# SIM3C166_B register map
File version: 1
CPU: 
Registers are 32-bit, read-write, reset 0x0 unless marked. A register's access mark holds for its fields unless they carry their own. Offsets are from the block's base; [hi:lo] are bit positions; {n}, {i} and the like mark numbered series; 'fields as' and 'values as' point back to an identical list.

## USART_0
Base 0x40000000
Same registers: USART_1 0x40001000
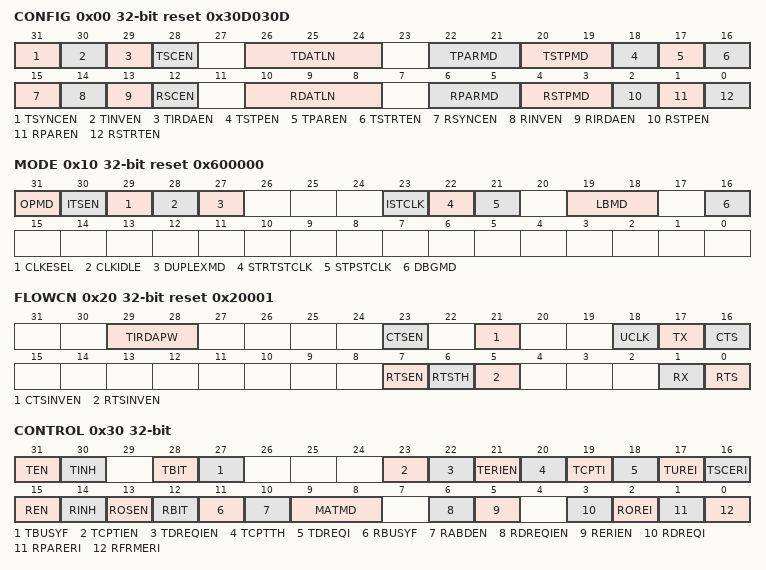
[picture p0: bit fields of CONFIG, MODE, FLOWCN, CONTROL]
0x00 CONFIG reset 0x30D030D — Module Configuration
  [31] TSYNCEN — Transmitter Synchronous Mode Enable.
    0=DISABLED (The transmitter operates in asynchronous mode.); 1=ENABLED (The transmitter operates in synchronous mode.)
  [30] TINVEN — Transmitter Invert Enable.
    0=DISABLED (Do not invert the TX pin signals (the TX idle state is high).); 1=ENABLED (Invert the TX pin signals (the TX idle state is low).)
  [29] TIRDAEN — Transmitter IrDA Enable.
    0=DISABLED (Disable IrDA transmit mode.); 1=ENABLED (Enable IrDA transmit mode.)
  [28] TSCEN — Transmitter Smartcard Parity Response Enable.
    0=DISABLED (The transmitter does not check for a Smartcard parity error response.); 1=ENABLED (The transmitter checks for a Smartcard parity error response.)
  [26:24] TDATLN — Transmitter Data Length.
    {v}={v+5}_BITS (v=0..3); 4=9_BITS_FIFO (9 bits. The 9th bit is taken from the FIFO data (normal mode).); 5=9_BITS_TBIT (9 bits. The 9th bit is set by the value of TBIT (fixed mode).)
  [22:21] TPARMD — Transmitter Parity Mode.
    0=ODD (Odd Parity.); 1=EVEN (Even Parity.); 2=MARK (Set (Parity = 1).); 3=SPACE (Clear (Parity = 0).)
  [20:19] TSTPMD — Transmitter Stop Mode.
    0=0P5_STOP (0.5 stop bit.); 1=1_STOP (1 stop bit.); 2=1P5_STOP (1.5 stop bits.); 3=2_STOP (2 stop bits.)
  [18] TSTPEN — Transmitter Stop Enable.
    0=DISABLED (Do not send stop bits during transmissions.); 1=ENABLED (Send stop bits during transmissions.)
  [17] TPAREN — Transmitter Parity Enable.
    0=DISABLED (Do not send a parity bit during transmissions.); 1=ENABLED (Send a parity bit during transmissions.)
  [16] TSTRTEN — Transmitter Start Enable.
    0=DISABLED (Do not generate a start bit during transmissions.); 1=ENABLED (Generate a start bit during transmissions.)
  [15] RSYNCEN — Receiver Synchronous Mode Enable.
    0=DISABLED (The receiver operates in asynchronous mode.); 1=ENABLED (The receiver operates in synchronous mode.)
  [14] RINVEN — Receiver Invert Enable.
    0=DISABLED (Do not invert the RX pin signals (the RX idle state is high).); 1=ENABLED (Invert the RX pin signals (the RX idle state is low).)
  [13] RIRDAEN — Receiver IrDA Enable.
    0=DISABLED (The receiver does not operate in IrDA mode.); 1=ENABLED (The receiver operates in IrDA mode.)
  [12] RSCEN — Receiver Smartcard Parity Response Enable.
    0=DISABLED (The receiver does not send a Smartcard parity error response.); 1=ENABLED (The receiver sends a Smartcard parity response.)
  [10:8] RDATLN — Receiver Data Length.
    {v}={v+5}_BITS (v=0..3); 4=9_BITS_STORED (9 bits. The 9th bit is stored in the FIFO (normal mode).); 5=9_BITS_MATCH (9 bits. The 9th bit is not stored in the FIFO (fixed mode). This mode is used when the 9th bit is only used for match operations (see MATMD).)
  [6:5] RPARMD — Receiver Parity Mode.
    values as TPARMD
  [4:3] RSTPMD — Receiver Stop Mode.
    values as TSTPMD
  [2] RSTPEN — Receiver Stop Enable.
    0=DISABLED (Do not expect stop bits during receptions.); 1=ENABLED (Expect stop bits during receptions.)
  [1] RPAREN — Receiver Parity Enable.
    0=DISABLED (Do not expect a parity bit during receptions.); 1=ENABLED (Expect a parity bit during receptions.)
  [0] RSTRTEN — Receiver Start Enable.
    0=DISABLED (Do not expect a start bit during receptions.); 1=ENABLED (Expect a start bit during receptions.)
0x10 MODE reset 0x600000 — Module Mode Select
  [31] OPMD — Operational Mode.
    0=SLAVE (The USART operates as a slave.); 1=MASTER (The USART operates as a master.)
  [30] ITSEN — Idle TX/UCLK Tristate Enable.
    0=DISABLED (The TX and UCLK (if in synchronous master mode) pins are always an output in this mode, even when idle.); 1=ENABLED (The TX pin is tristated when idle. If ISTCLK is cleared to 0 and the transmitter is configured in synchronous master mode, the UCLK pin will also be tristated when idle.)
  [29] CLKESEL — Clock Edge Select.
    0=FALLING (The clock falls in the middle of each bit.); 1=RISING (The clock rises in the middle of each bit.)
  [28] CLKIDLE — Clock Idle State.
    0=IDLE_LOW (The synchronous clock is low when idle.); 1=IDLE_HIGH (The synchronous clock is high when idle.)
  [27] DUPLEXMD — Duplex Mode.
    0=FULL_DUPLEX (Full-duplex mode. The transmitter and receiver can operate simultaneously.); 1=HALF_DUPLEX (Half-duplex mode. The transmitter automatically inhibits when the receiver is active and the receiver automatically inhibits when the transmitter is active.)
  [23] ISTCLK — Idle Clock Control.
    0=DISABLED (When the USART is a clock master and CLKESEL is not equal to CLKIDLE, the clock is held idle between transmissions. When the USART is a clock master and CLKESEL equals CLKIDEL, the clock will still be generated between transmissions. When the USART is a clock slave, the USART will begin transmissions without waiting for the next clock edge.); 1=ENABLED (When the USART is a clock master, the clock is generated between transmissions or receptions. When the USART is a clock slave, the USART will wait until the next clock edge before transmitting.)
  [22] STRTSTCLK — Start State Clock Control.
    0=DISABLED (When the USART is a clock master, the clock is held idle during a start bit.); 1=ENABLED (When the USART is a clock master, the clock is generated during a start bit.)
  [21] STPSTCLK — Stop State Clock Control.
    0=DISABLED (When the USART is a clock master, the clock is not generated during stop bits.); 1=ENABLED (When the USART is a clock master, the clock is generated during stop bits.)
  [19:18] LBMD — Loop Back Mode.
    0=DISABLED (Loop back is disabled and the TX and RX signals are connected to the corresponding external pins.); 1=RXONLY (Receive loop back. The receiver input path is disconnected from the RX pin and internally connected to the transmitter. Data transmitted will be sent out on TX and also received by the device.); 2=TXONLY (Transmit loop back. The transmitter output path is disconnected from the TX pin and the RX input pin is internally looped back out to the TX pin. Data received at RX will be received by the device and also sent directly back out on TX.); 3=BOTH (Full loop back. Internally, the transmitter output is routed back to the receiver input. Neither the transmitter nor receiver are connected to external device pins. The device pin RX is looped back to TX in a similar fashion. Data transmitted on TX will be sent directly back in on RX.)
  [16] DBGMD — USART Debug Mode.
    0=RUN (The USART module will continue to operate while the core is halted in debug mode.); 1=HALT (A debug breakpoint will cause the USART module to halt. Any active transmissions and receptions will complete first.)
0x20 FLOWCN reset 0x20001 — Flow Control
  [29:28] TIRDAPW — Transmit IrDA Pulse Width.
    0=1_16TH (The IrDA pulse width is 1/16th of a bit period.); 1=1_8TH (The IrDA pulse width is 1/8th of a bit period.); 2=3_16TH (The IrDA pulse width is 3/16th of a bit period.); 3=1_4TH (The IrDA pulse width is 1/4th of a bit period.)
  [23] CTSEN — CTS Enable.
    0=DISABLED (The CTS pin state does not affect transmissions.); 1=ENABLED (Transmissions will begin only if the CTS pin (after optional inversion) is low.)
  [21] CTSINVEN — CTS Invert Enable.
    0=DISABLED (The USART does not invert CTS.); 1=ENABLED (The USART inverts CTS.)
  [18] UCLK — UCLK State.
    0=LOW (The UCLK pin is low.); 1=HIGH (The UCLK pin is high.)
  [17] TX — TX State.
    0=LOW (The TX pin (before optional inversion) is low.); 1=HIGH (The TX pin (before optional inversion) is high.)
  [16] CTS ro — CTS State.
    0=LOW (Indicates the CTS pin state (after optional inversion) is low.); 1=HIGH (Indicates the CTS pin state (after optional inversion) is high.)
  [7] RTSEN — RTS Enable.
    0=DISABLED (The RTS state is not changed by hardware. The RTS bit can be written only when hardware RTS is disabled (RTSEN = 0).); 1=ENABLED (Hardware sets RTS when the receive FIFO is at or above the threshold set by RTSTH and clears RTS otherwise.)
  [6] RTSTH — RTS Threshold Control.
    0=FULL (RTS is de-asserted when the receive FIFO and shift register are full and no more incoming data can be stored.); 1=ONE_BYTE_FREE (RTS is de-asserted when the receive FIFO and shift register are nearly full and only one more data can be received.)
  [5] RTSINVEN — RTS Invert Enable.
    0=DISABLED (The USART does not invert the RTS signal before driving the pin.); 1=ENABLED (The USART inverts the RTS signal driving the pin.)
  [1] RX ro — RX Pin Status.
    0=LOW (RX pin (after optional inversion) is low.); 1=HIGH (RX pin (after optional inversion) is high.)
  [0] RTS — RTS State.
    0=LOW (RTS pin (before optional inversion) is driven low.); 1=HIGH (RTS pin (before optional inversion) is driven high.)
0x30 CONTROL — Module Control
  [31] TEN — Transmitter Enable.
    0=DISABLED (Disable the transmitter. When cleared, the transmitter immediately aborts any active transmission. Clearing this bit does not automatically flush the transmit FIFO.); 1=ENABLED (Enable the transmitter. The transmitter will initiate a transmission when data becomes available in the transmit FIFO.)
  [30] TINH — Transmit Inhibit.
    0=INACTIVE (The transmitter operates normally.); 1=ACTIVE (Transmissions are inhibited. The transmitter will stall after any current transmission is complete.)
  [28] TBIT — Last Transmit Bit.
    0=NOT_SET; 1=SET
  [27] TBUSYF ro — Transmitter Busy Flag.
    0=NOT_SET (The USART transmitter is idle.); 1=SET (The USART transmitter is active and transmitting.)
  [23] TCPTIEN — Transmit Complete Interrupt Enable.
    0=DISABLED (Disable the transmit complete interrupt.); 1=ENABLED (Enable the transmit complete interrupt. A transmit interrupt is generated when TCPTI is set to 1.)
  [22] TDREQIEN — Transmit Data Request Interrupt Enable.
    0=DISABLED (Disable the transmit data request interrupt.); 1=ENABLED (Enable the transmit data request interrupt. A transmit interrupt is asserted when TDREQI is set to 1.)
  [21] TERIEN — Transmit Error Interrupt Enable.
    0=DISABLED (Disable the transmit error interrupt.); 1=ENABLED (Enable the transmit error interrupt. A transmit interrupt is generated when TUREI or TSCERI is set to 1.)
  [20] TCPTTH — Transmit Complete Threshold.
    0=SET_ON_TX (A transmit is completed (TCPTI = 1) at the end of each transmission.); 1=SET_ON_EMPTY (A transmit is completed (TCPTI = 1) only at the end of a transmission when no more data is available to transmit.)
  [19] TCPTI — Transmit Complete Interrupt Flag.
    0=NOT_SET (Read: A transmit has not completed since TCPTI was last cleared. Write: Clear the interrupt.); 1=SET (Read: A byte was transmitted (TCCPTH = 0) or the last available byte was transmitted (TCPTTH = 1). Write: Force a transmit complete interrupt.)
  [18] TDREQI ro — Transmit Data Request Interrupt Flag.
    0=NOT_SET (The transmitter is not requesting more FIFO data.); 1=SET (The transmitter is requesting more FIFO data.)
  [17] TUREI — Transmit Underrun Error Interrupt Flag.
    0=NOT_SET (Read: A transmitter underrun has not occurred since TUREI was last cleared. Write: Clear the interrupt.); 1=SET (Read: A transmitter underrun occurred. Write: Force a transmitter underrun interrupt.)
  [16] TSCERI — Smartcard Parity Error Interrupt Flag.
    0=NOT_SET (Read: A Smartcard parity error has not occurred since TSCERI was last cleared. Write: Clear the interrupt.); 1=SET (Read: A Smartcard parity error occurred. Write: Force a Smartcard parity error interrupt.)
  [15] REN — Receiver Enable.
    0=DISABLED (Disable the receiver. The receiver can receive one data transaction only if ROSEN is set.); 1=ENABLED (Enable the receiver.)
  [14] RINH — Receiver Inhibit.
    0=INACTIVE (The receiver operates normally.); 1=ACTIVE (RTS is immediately asserted when RINH is set. The receiver will complete any ongoing reception, but ignore all traffic after that.)
  [13] ROSEN — Receiver One-Shot Enable.
    0=DISABLED (Disable one-shot receive mode.); 1=ENABLED (Enable one-shot receive mode.)
  [12] RBIT — Last Receive Bit.
    0=NOT_SET; 1=SET
  [11] RBUSYF ro — Receiver Busy Flag.
    0=NOT_SET (The USART receiver is idle.); 1=SET (The USART receiver is receiving data.)
  [10] RABDEN — Receiver Auto-Baud Enable.
    0=DISABLED (Disable receiver auto-baud.); 1=ENABLED (Enable receiver auto-baud.)
  [9:8] MATMD — Match Mode.
    0=OFF (Disable the match function.); 1=MCE ((MCE) Data whose last data bit equals RBIT is accepted and stored.); 2=FRAME ((Frame) A framing error is asserted if the last received bit matches RBIT.); 3=STORE ((Store) Store the last incoming data bit in RBIT. This mode can be used inconjunction with the RDATLN setting.)
  [6] RDREQIEN — Receive Data Request Interrupt Enable.
    0=DISABLED (Disable the read data request interrupt.); 1=ENABLED (Enable the read data request interrupt. A receive interrupt is generated when RDREQI is set to 1.)
  [5] RERIEN — Receive Error Interrupt Enable.
    0=DISABLED (Disable the receive error interrupt.); 1=ENABLED (Enable the receive error interrupt. A receive error interrupt is asserted when ROREI, RFRMERI, or RPARERI is set to 1.)
  [3] RDREQI ro — Receive Data Request Interrupt Flag.
    0=NOT_SET (Fewer than RFTH FIFO slots are filled with data.); 1=SET (At least RFTH FIFO slots are filled with data.)
  [2] ROREI — Receive Overrun Error Interrupt Flag.
    0=NOT_SET (Read: A receiver overrun has not occurred since ROREI was last cleared. Write: Clear the interrupt.); 1=SET (Read: A receiver overrun occurred. Write: Force a receiver overrun interrupt.)
  [1] RPARERI — Receive Parity Error Interrupt Flag.
    0=NOT_SET (Read: An invalid parity bit has not been received since RPARERI was last cleared. Write: Clear the interrupt.); 1=SET (Read: An invalid parity bit has been received since RPARERI was last cleared. Write: Force a parity error interrupt.)
  [0] RFRMERI — Receive Frame Error Interrupt Flag.
    0=NOT_SET (Read: A frame error has not occurred since RFRMERI was last cleared. Write: Clear the interrupt.); 1=SET (Read: A frame error occurred. Write: Force a frame error interrupt.)
0x40 IPDELAY — Inter-Packet Delay
  [23:16] IPDELAY — Inter-Packet Delay.
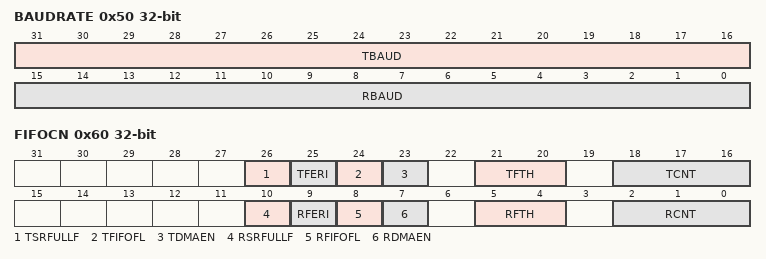
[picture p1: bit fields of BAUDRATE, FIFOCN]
0x50 BAUDRATE — Transmit and Receive Baud Rate
  [31:16] TBAUD — Transmitter Baud Rate Control.
  [15:0] RBAUD — Receiver Baud Rate Control.
0x60 FIFOCN — FIFO Control
  [26] TSRFULLF ro — Transmit Shift Register Full Flag.
    0=NOT_SET (The transmit shift register is not full.); 1=SET (The transmit shift register is full.)
  [25] TFERI — Transmit FIFO Error Interrupt Flag.
    0=NOT_SET (A transmit FIFO error has not occurred since TFERI was last cleared.); 1=SET (A transmit FIFO error occurred.)
  [24] TFIFOFL — Transmit FIFO Flush.
    1=SET (Flush the contents of the transmit FIFO. If data is pending in the transmit shift register but a transmit has not begun, the shift register is also flushed.)
  [23] TDMAEN — Transmitter DMA Enable.
    0=DISABLED (Disable transmit FIFO DMA requests.); 1=ENABLED (Enable transmit FIFO DMA requests.)
  [21:20] TFTH — Transmit FIFO Threshold.
    0=ONE (A DMA request or transmit data request interrupt (TDREQI) is asserted when >= 1 FIFO slot is empty.); 1=TWO (A DMA request or transmit data request interrupt (TDREQI) is asserted when >= 2 FIFO slots are empty.); 2=FOUR (A DMA request or transmit data request interrupt (TDREQ) is asserted when >= 4 FIFO slots are empty.)
  [18:16] TCNT ro — Transmit FIFO Count.
  [10] RSRFULLF ro — Receive Shift Register Full Flag.
    0=NOT_SET (The receive data shift register is not full.); 1=SET (The receive data shift register is full.)
  [9] RFERI — Receive FIFO Error Interrupt Flag.
    0=NOT_SET (A receive FIFO error has not occurred since RFERI was last cleared.); 1=SET (A receive FIFO error occurred.)
  [8] RFIFOFL — Receive FIFO Flush.
    1=SET (Flush the contents of the receive FIFO and any data in the receive shift register.)
  [7] RDMAEN — Receiver DMA Enable.
    0=DISABLED (Disable receive FIFO DMA requests.); 1=ENABLED (Enable receive FIFO DMA requests.)
  [5:4] RFTH — Receive FIFO Threshold.
    0=ONE (A DMA request or read data request interrupt (RDREQI) is asserted when >= 1 FIFO slot is full.); 1=TWO (A DMA request or read data request interrupt (RDREQI) is asserted when >= 2 FIFO slots are full.); 2=FOUR (A DMA request or read data request interrupt (RDREQ) is asserted when >= 4 FIFO slots are full.)
  [2:0] RCNT ro — Receive FIFO Count.
0x70 DATA read-has-side-effects — FIFO Input/Output Data
  [31:0] DATA — FIFO Data.
